# apollo510 register map
Vendor: Ambiq Micro; Series: Apollo; File version: 1.0
CPU: CM55 r1p1, little endian, MPU, FPU, double-precision FPU, DSP, I-cache, D-cache, VTOR, ITCM, DTCM, 4 interrupt priority bits, 0 interrupts, 8 SAU regions
Registers are 32-bit, read-write, reset 0x0 unless marked. A register's access mark holds for its fields unless they carry their own. Offsets are from the block's base; [hi:lo] are bit positions; {n}, {i} and the like mark numbered series; 'fields as' and 'values as' point back to an identical list.

## SDIO0 (part 1 of 2) — SDIO Control Registers
Base 0x40070000
Same registers: SDIO1 0x40071000
0x00 SDMA — SDMA system address
  [31:0] SDMASYSTEMADDRESS — This register contains the physical system memory address used for DMA transfers or the second argument for the Auto CMD23. (1) SDMA System Address This register contains the system memory address for a SDMA transfer. When the Host Controller stops a SDMA transfer, this register shall point to the system address of the next contiguous data position. It can be accessed only if no transaction is executing (i.e., after a transaction has stopped). Read operations during transfers may return an invalid value. The Host Driver shall initialize this register before starting a SDMA transaction. After SDMA has stopped, the next system address of the next contiguous data position can be read from this register. The SDMA transfer waits at the every boundary specified by the Host SDMA Buffer Boundary in the Block Size register. The Host Controller generates DMA Interrupt to request the Host Driver to update this register. The Host Driver sets the next system address of the next data position to this register. When the most upper byte of this register (003h) is written, the Host Controller restarts the SDMA transfer. When restarting SDMA by the Resume command or by setting Continue Request in the Block Gap Control register, the Host Controller shall start at the next contiguous address stored here in the SDMA System Address register. ADMA does not use this register (2) Argument 2 This register is used with the Auto CMD23 to set a 32-bit block count value to the argument of the CMD23 while executing Auto CMD23. If Auto CMD23 is used with ADMA, the full 32-bit block count value can be used. If Auto CMD23 is used without AMDA, the available block count value is limited by the Block Count register. 65535 blocks is the maximum value in this case.
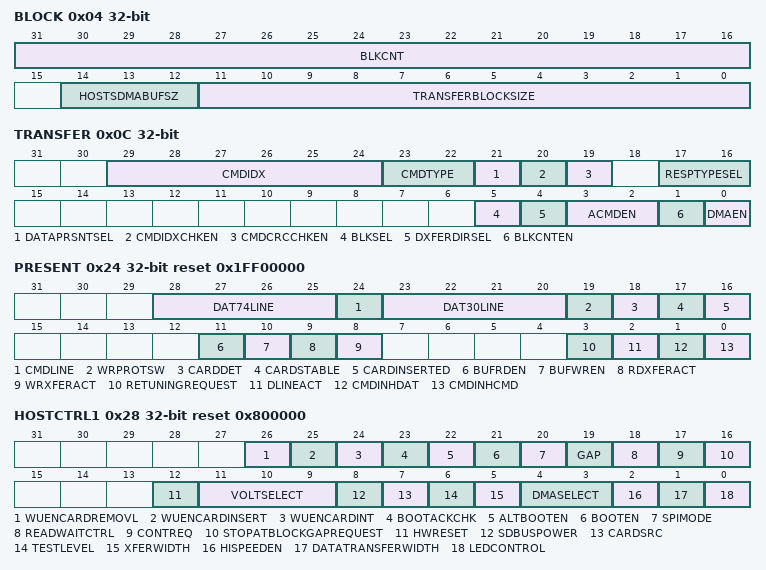
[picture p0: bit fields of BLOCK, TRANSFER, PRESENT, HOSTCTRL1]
0x04 BLOCK — Block size
  [31:16] BLKCNT — This register is enabled when Block Count Enable in the Transfer Mode register is set to 1 and is valid only for multiple block transfers. The HC decrements the block count after each block transfer and stops when the count reaches zero. It can be accessed only if no transaction is executing (i.e. after a transaction has stopped). Read operations during transfer return an invalid value and write operations shall be ignored. When saving transfer context as a result of Suspend command, the number of blocks yet to be transferred can be determined by reading this register. When restoring transfer context prior to issuing a Resume command, the HD shall restore the previously save block count.
    0=STOPCNT (Stop Count); 1=1BLOCK; 2=2BLOCKS (2 blocks (and so on from 1-65535)); 0xFFFF=65535BLOCKS
  [14:12] HOSTSDMABUFSZ — To perform long DMA transfer, System Address register shall be updated at every system boundary during DMA transfer. These bits specify the size of contiguous buffer in the system memory. The DMA transfer shall wait at the every boundary specified by these fields and the HC generates the DMA Interrupt to request the HD to update the System Address register. These bits shall support when the DMA Support in the Capabilities register is set to 1 and this function is active when the DMA Enable in the Transfer Mode register is set to 1.
    0=4KB (4KB(Detects A11 Carry out)); 1=8KB (8KB(Detects A12 Carry out)); 2=16KB (16KB(Detects A13 Carry out)); 3=32KB (32KB(Detects A14 Carry out)); 4=64KB (64KB(Detects A15 Carry out)); 5=128KB (128KB(Detects A16 Carry out)); 6=256KB (256KB(Detects A17 Carry out)); 7=512KB (512KB(Detects A18 Carry out))
  [11:0] TRANSFERBLOCKSIZE — This register specifies the block size for block data transfers for CMD17, CMD18, CMD24, CMD25, and CMD53. It can be accessed only if no transaction is executing (i.e after a transaction has stopped). Read operations during transfer return an invalid value and write operations shall be ignored.
    0=NODATAXFER (No Data Transfer); 1=1BYTE; 2=2BYTES; 3=3BYTES; 4=4BYTES (4 Bytes (and so on from 1-2048)); 0x1FF=511BYTES; 0x200=512BYTES; 0x800=2048BYTES
0x08 ARGUMENT1
  [31:0] CMDARG1 — The SD Command Argument is specified as bit39-8 of Command-Format.
0x0C TRANSFER — Transfer mode
  [29:24] CMDIDX — This bit shall be set to the command number (CMD0-63, ACMD063).
  [23:22] CMDTYPE — There are three types of special commands. Suspend, Resume and Abort. These bits shall bet set to 00b for all other commands. Suspend Command If the Suspend command succeeds, the HC shall assume the SD Bus has been released and that it is possible to issue the next command which uses the DAT line. The HC shall de-assert Read Wait for read transactions and stop checking busy for write transactions. The Interrupt cycle shall start, in 4-bit mode. If the Suspend command fails, the HC shall maintain its current state. and the HD shall restart the transfer by setting Continue Request in the Block Gap Control Register. Resume Command The HD re-starts the data transfer by restoring the registers in the range of 000-00Dh. The HC shall check for busy before starting write transfers. Abort Command If this command is set when executing a read transfer, the HC shall stop reads to the buffer. If this command is set when executing a write transfer, the HC shall stop driving the DAT line. After issuing the Abort command, the HD should issue a software reset
    0=NORMAL; 1=SUSPEND; 2=RESUME; 3=ABORT
  [21] DATAPRSNTSEL — This bit is set to 1 to indicate that data is present and shall be transferred using the DAT line. If is set to 0 for the following: 1. Commands using only CMD line (ex. CMD52) 2. Commands with no data transfer but using busy signal on DAT[0] line (R1b or R5b ex. CMD38) 3. Resume Command
    0=NODATAPRESENT; 1=DATAPRESENT
  [20] CMDIDXCHKEN — If this bit is set to 1, the HC shall check the index field in the response to see if it has the same value as the command index. If it is not, it is reported as a Command Index Error. If this bit is set to 0, the Index field is not checked.
    0=DISABLE; 1=ENABLE
  [19] CMDCRCCHKEN — If this bit is set to 1, the HC shall check the CRC field in the response. If an error is detected, it is reported as a Command CRC Error. If this bit is set to 0, the CRC field is not checked.
    0=DISABLE; 1=ENABLE
  [17:16] RESPTYPESEL — Response Type Select
    0=NORESPONSE; 1=LEN136 (Response length 136); 2=LEN48 (Response length 48); 3=LEN48CHKBUSY (Response length 48 check Busy after response)
  [5] BLKSEL — This bit enables multiple block data transfers.
    0=SINGLEBLOCK; 1=MULTIPLEBLOCK
  [4] DXFERDIRSEL — Data Transfer Direction Select. This bit defines the direction of data transfers.
    0=WRITE (Write (Host to Card)); 1=READ (Read (Card to Host))
  [3:2] ACMDEN — This field determines use of auto command functions. There are two methods to stop Multiple-block read and write operation. (1) Auto CMD12 Enable Multiple-block read and write commands for memory require CMD12 to stop the operation. When this field is set to 01b, the Host Controller issues CMD12 automatically when last block transfer is completed. Auto CMD12 error is indicated to the Auto CMD Error Status register. The Host Driver shall not set this bit if the command does not require CMD12. (2) Auto CMD23 Enable When this bit field is set to 10b, the Host Controller issues a CMD23 automatically before issuing a command specified in the Command Register The following conditions are required to use the Auto CMD23.
    0=DISABLED (Auto Command Disabled); 1=CMD12ENABLE (Auto CMD12 Enable); 2=CMD23ENABLE (Auto CMD23 Enable)
  [1] BLKCNTEN — This bit is used to enable the Block count register, which is only relevant for multiple block transfers. When this bit is 0, the Block Count register is disabled, which is useful in executing an infinite transfer.
    0=DISABLE; 1=ENABLE
  [0] DMAEN — DMA can be enabled only if DMA Support bit in the Capabilities register is set. If this bit is set to 1, a DMA operation shall begin when the HD writes to the upper byte of Command register (00Fh).
    0=DISABLE; 1=ENABLE
{0x10+4i} RESPONSE{i} (i=0..3)
  [31:0] CMDRESP{i} — R[] refers to a bit range within the response data as transmitted on the SD Bus, REP[] refers to a bit range within the Response register.
0x20 BUFFER — Buffer data port
  [31:0] BUFFERDATA — The Host Controller Buffer can be accessed through this 32-bit Data Port Register.
0x24 PRESENT reset 0x1FF00000 — Present state
  [28:25] DAT74LINE — This status is used to check DAT line level to recover from errors, and for debugging.
    8=DAT7; 4=DAT6; 2=DAT5; 1=DAT4
  [24] CMDLINE — This status is used to check CMD line level to recover from errors, and for debugging.
  [23:20] DAT30LINE — This status is used to check DAT line level to recover from errors, and for debugging. This is especially useful in detecting the busy signal level from DAT[0].
    8=DAT3; 4=DAT2; 2=DAT1; 1=DAT0
  [19] WRPROTSW — The Write Protect Switch is supported for memory and combo cards. This bit reflects the SDWP# pin.
    0=WRITEPROTECTED (Write protected (SDWP# = 0)); 1=WRITEENABLED (Write enabled (SDWP# = 1))
  [18] CARDDET — This bit reflects the inverse value of the SDCD# pin.
    0=NOCARDPRESENT (No Card present (SDCD# = 1)); 1=CARDPRESENT (Card present (SDCD# = 0))
  [17] CARDSTABLE — This bit is used for testing. If it is 0, the Card Detect Pin Level is not stable. If this bit is set to 1, it means the Card Detect Pin Level is stable. The Software Reset For All in the Software Reset Register shall not affect this bit.
    0=RESET_DEBOUNCING_NOCARD (Reset or Debouncing or No Card); 1=CARDINSERTED
  [16] CARDINSERTED — This bit indicates whether a card has been inserted. Changing from 0 to 1 generates a Card Insertion interrupt in the Normal Interrupt Status register and changing from 1 to 0 generates a Card Removal Interrupt in the Normal Interrupt Status register. The Software Reset For All in the Software Reset register shall not affect this bit. If a Card is removed while its power is on and its clock is oscillating, the HC shall clear SD Bus Power in the Power Control register and SD Clock Enable in the Clock control register. In addition the HD should clear the HC by the Software Reset For All in Software register. The card detect is active regardless of the SD Bus Power.
    values as CARDSTABLE
  [11] BUFRDEN — This status is used for non-DMA read transfers. This read only flag indicates that valid data exists in the host side buffer status. If this bit is 1, readable data exists in the buffer. A change of this bit from 1 to 0 occurs when all the block data is read from the buffer. A change of this bit from 0 to 1 occurs when all the block data is ready in the buffer and generates the Buffer Read Ready Interrupt.
    0=DISABLE (Read Disable); 1=ENABLE (Read Enable.)
  [10] BUFWREN — This status is used for non-DMA write transfers. This read only flag indicates if space is available for write data. If this bit is 1, data can be written to the buffer. A change of this bit from 1 to 0 occurs when all the block data is written to the buffer. A change of this bit from 0 to 1 occurs when top of block data can be written to the buffer and generates the Buffer Write Ready Interrupt.
    0=DISABLE (Write Disable); 1=ENABLE (Write Enable.)
  [9] RDXFERACT — This status is used for detecting completion of a read transfer. This bit is set to 1 for either of the following conditions: After the end bit of the read command When writing a 1 to continue Request in the Block Gap Control register to restart a read transfer This bit is cleared to 0 for either of the following conditions: When the last data block as specified by block length is transferred to the system. When all valid data blocks have been transferred to the system and no current block transfers are being sent as a result of the Stop At Block Gap Request set to 1. A transfer complete interrupt is generated when this bit changes to 0.
    1=TRANSFERRING (Transferring data); 0=NOVALIDATA (No valid data)
  [8] WRXFERACT — This status indicates a write transfer is active. If this bit is 0, it means no valid write data exists in the HC. This bit is set in either of the following cases: After the end bit of the write command. When writing a 1 to Continue Request in the Block Gap Control register to restart a write transfer. This bit is cleared in either of the following cases: After getting the CRC status of the last data block as specified by the transfer count (Single or Multiple) After getting a CRC status of any block where data transmission is about to be stopped by a Stop At Block Gap Request. During a write transaction, a Block Gap Event interrupt is generated when this bit is changed to 0, as a result of the Stop At Block Gap Request being set. This status is useful for the HD in determining when to issue commands during write busy.
    1=TRANSFERRING (transferring data); 0=NOVALIDDATA
  [3] RETUNINGREQUEST — Re-Tuning Request Host Controller may request Host Driver to execute re-tuning sequence by setting this bit when the data window is shifted by temperature drift and a tuned sampling point does not have a good margin to receive correct data. This bit is cleared when a command is issued with setting Execute Tuning in the Host Control 2 register. Changing of this bit from 0 to 1 generates Re-Tuning Event. Refer to Normal Interrupt registers for more detail. This bit isn't set to 1 if Sampling Clock Select in the Host Control 2 register is set to 0 (using fixed sampling clock).
    1=RETUNENEEDED (Sampling clock needs re-tuning); 0=WELLTUNED (Fixed or well tuned sampling clock)
  [2] DLINEACT — This bit indicates whether one of the DAT line on SD bus is in use.
    1=ACTIVE (DAT line active); 0=INACTIVE (DAT line inactive)
  [1] CMDINHDAT — This status bit is generated if either the DAT Line Active or the Read transfer Active is set to 1. If this bit is 0, it indicates the HC can issue the next SD command. Commands with busy signal belong to Command Inhibit (DAT) (ex. R1b, R5b type). Changing from 1 to 0 generates a Transfer Complete interrupt in the Normal interrupt status register. Note: The SD Host Driver can save registers in the range of 000-00Dh for a suspend transaction after this bit has changed from 1 to 0.
    1=DONTISSUE (cannot issue command which uses the DAT line); 0=ISSUE (Can issue command which uses the DAT line)
  [0] CMDINHCMD — If this bit is 0, it indicates the CMD line is not in use and the HC can issue a SD command using the CMD line. This bit is set immediately after the Command register (00Fh) is written. This bit is cleared when the command response is received. Even if the Command Inhibit (DAT) is set to 1, Commands using only the CMD line can be issued if this bit is 0. Changing from 1 to 0 generates a Command complete interrupt in the Normal Interrupt Status register. If the HC cannot issue the command because of a command conflict error or because of Command Not Issued By Auto CMD12 Error, this bit shall remain 1 and the Command Complete is not set. Status issuing Auto CMD12 is not read from this bit. Auto CMD12 and Auto CMD23 consist of two responses. In this case, this bit is not cleared by the response of CMD12 or CMD23 but cleared by the response of a read/write command. Status issuing Auto CMD12 is not read from this bit. So if a command is issued during Auto CMD12 operation, Host Controller shall manage to issue two commands: CMD12 and a command set by Command register. Note: DAT line active indicates whether one of the DAT line is on SD bus is in use. (a) In the case of read transactions This status indicates whether a read transfer is executing on the SD Bus. Changing this value from 1 to 0 generates a Block Gap Event interrupt in the Normal Interrupt Status register, as the result of the Stop At Block Gap Request being set. This bit shall be set in either of the following cases: (1) After the end bit of the read command. (2) When writing a 1 to Continue Request in the Block Gap Control register to restart a read transfer. This bit shall be cleared in either of the following cases: (1) When the end bit of the last data block is sent from the SD Bus to the Host Controller. In case of ADMA2, the last block is designated by the last transfer of Descriptor Table. (2) When a read transfer is stopped at the block gap initiated by a Stop At Block Gap Request. The Host Controller shall stop read operation at the start of the interrupt cycle of the next block gap by driving Read Wait or stopping SD clock. If the Read Wait signal is already driven (due to data buffer cannot receive data), the Host Controller can continue to stop read operation by driving the Read Wait signal. It is necessary to support Read Wait in order to use suspend / resume function. (b) In the case of write transactions This status indicates that a write transfer is executing on the SD Bus. Changing this value from 1 to 0 generate a Transfer Complete interrupt in the Normal Interrupt Status register. This bit shall be set in either of the following cases: (1) After the end bit of the write command. (2) When writing to 1 to Continue Request in the Block Gap Control register to continue a write transfer. This bit shall be cleared in either of the following cases: (1) When the SD card releases write busy of the last data block. If SD card does not drive busy signal for 8 SD Clocks, the Host Controller shall consider the card drive Not Busy. In case of ADMA2, the last block is designated by the last transfer of Descriptor Table. (2) When the SD card releases write busy prior to waiting for write transfer as a result of a Stop At Block Gap Request. (c) Command with busy This status indicates whether a command indicates busy (ex. erase command for memory) is executing on the SD Bus. This bit is set after the end bit of the command with busy and cleared when busy is de-asserted. Changing this bit from 1 to 0 generate a Transfer Complete interrupt in the Normal Interrupt Status register. Note: The HD can issue cmd0, cmd12, cmd13 (for memory) and cmd52 (for SDIO) when the DAT lines are busy during data transfer. These commands can be issued when Command Inhibit (CMD) is set to zero. Other commands shall be issued when Command Inhibit (DAT) is set to zero.
    1=DONTISSUE (CMD line is in use); 0=ISSUE (Indicates that the CMD line is not in use and the HC can issue a SD command using the CMD line.)
0x28 HOSTCTRL1 reset 0x800000 — Host control 1
  [26] WUENCARDREMOVL — This bit enables wakeup event via Card Removal assertion in the Normal Interrupt Status register. FN_WUS (Wake up Support) in CIS does not affect this bit.
    1=ENABLE; 0=DISABLE
  [25] WUENCARDINSERT — This bit enables wakeup event via Card Insertion assertion in the Normal Interrupt Status register. FN_WUS (Wake up Support) in CIS does not affect this bit.
    1=ENABLE; 0=DISABLE
  [24] WUENCARDINT — This bit enables wakeup event via Card Interrupt assertion in the Normal Interrupt Status register. This bit can be set to 1 if FN_WUS (Wake Up Support) in CIS is set to 1.
    1=ENABLE; 0=DISABLE
  [23] BOOTACKCHK — To check for the boot acknowledge in boot operation.
    1=WAIT (wait for boot ack from eMMC card); 0=NOWAIT (Will not wait for boot ack from eMMC card)
  [22] ALTBOOTEN — To start boot code access in alternative mode.
    1=START (To start alternate boot mode access); 0=STOP (To stop alternate boot mode access)
  [21] BOOTEN — To start boot code access
    1=START (To start boot code access); 0=STOP (To stop boot code access)
  [20] SPIMODE — SPI mode enable bit.
    1=SPI (SPI mode); 0=SD (SD mode)
  [19] GAP — This bit is valid only in 4-bit mode of the SDIO card and selects a sample point in the interrupt cycle. Setting to 1 enables interrupt detection at the block gap for a multiple block transfer. If the SD card cannot signal an interrupt during a multiple block transfer, this bit should be set to 0. When the HD detects an SD card insertion, it shall set this bit according to the CCCR of the SDIO card.
  [18] READWAITCTRL — The read wait function is optional for SDIO cards. If the card supports read wait, set this bit to enable use of the read wait protocol to stop read data using DAT[2] line. Otherwise the HC has to stop the SD clock to hold read data, which restricts commands generation. When the HD detects an SD card insertion, it shall set this bit according to the CCCR of the SDIO card. If the card does not support read wait, this bit shall never be set to 1 otherwise DAT line conflict may occur. If this bit is set to 0, Suspend / Resume cannot be supported
    1=ENABLE (Enable Read Wait Control); 0=DISABLE (Disable Read Wait Control)
  [17] CONTREQ — This bit is used to restart a transaction which was stopped using the Stop At Block Gap Request. To cancel stop at the block gap, set Stop At block Gap Request to 0 and set this bit to restart the transfer. The HC automatically clears this bit in either of the following cases: 1) In the case of a read transaction, the DAT Line Active changes from 0 to 1 as a read transaction restarts. 2) In the case of a write transaction, the Write transfer active changes from 0 to 1 as the write transaction restarts. Therefore it is not necessary for Host driver to set this bit to 0. If Stop At Block Gap Request is set to 1, any write to this bit is ignored.
    1=RESTART; 0=IGNORED
  [16] STOPATBLOCKGAPREQUEST — This bit is used to stop executing a transaction at the next block gap for non- DMA,SDMA and ADMA transfers. Until the transfer complete is set to 1, indicating a transfer completion the HD shall leave this bit set to 1. Clearing both the Stop At Block Gap Request and Continue Request shall not cause the transaction to restart. Read Wait is used to stop the read transaction at the block gap. The HC shall honour Stop At Block Gap Request for write transfers, but for read transfers it requires that the SD card support Read Wait. Therefore the HD shall not set this bit during read transfers unless the SD card supports Read Wait and has set Read Wait Control to 1. In case of write transfers in which the HD writes data to the Buffer Data Port register, the HD shall set this bit after all block data is written. If this bit is set to 1, the HD shall not write data to Buffer data port register. This bit affects Read Transfer Active, Write Transfer Active, DAT line active and Command Inhibit (DAT) in the Present State register.
    1=STOP; 0=TRANSFER
  [12] HWRESET — Hardware reset signal is generated for eMMC card when this bit is set
    1=ASSERT (Drives the hardware reset pin as ZERO (Active LOW to eMMC card)); 0=DEASSERT (Deassert the hardware reset pin)
  [11:9] VOLTSELECT — By setting these bits, the HD selects the voltage level for the SD card. Before setting this register, the HD shall check the voltage support bits in the capabilities register. If an unsupported voltage is selected, the Host System shall not supply SD bus voltage. All voltage select values not enumerated here are reserved.
    7=3_3V (3.3 V(Typ.)); 6=3_0V (3.0 V(Typ.)); 5=1_8V (1.8 V(Typ.))
  [8] SDBUSPOWER — Before setting this bit, the SD host driver shall set SD Bus Voltage Select. If the HC detects the No Card State, this bit shall be cleared.
    1=POWERON; 0=POWEROFF
  [7] CARDSRC — This bit selects source for card detection.
    1=TEST (The card detect test level is selected); 0=SDCD (SDCD is selected (for normal use))
  [6] TESTLEVEL — This bit is enabled while the Card Detect Signal Selection is set to 1 and it indicates card inserted or not. Generates (card ins or card removal) interrupt when the normal int sts enable bit is set.
    1=CARDINSERTED; 0=NOCARD
  [5] XFERWIDTH — This bit controls 8-bit bus width mode for embedded device. Support of this function is indicated in 8-bit Support for Embedded Device in the Capabilities register. If a device supports 8-bit bus mode, this bit may be set to 1. If this bit is 0, bus width is controlled by Data Transfer Width in the Host Control 1 register.This bit is not effective when multiple devices are installed on a bus slot (Slot Type is set to 10b in the Capabilities register). In this case, each device bus width is controlled by Bus Width Preset field in the Shared Bus register.
    1=8BIT (8-bit Bus Width); 0=XFER (Bus Width is selected by Data Transfer Width)
  [4:3] DMASELECT — One of supported DMA modes can be selected. The host driver shall check support of DMA modes by referring the Capabilities register.
    0=SDMA (SDMA is selected); 1=ADMA132 (32-bit Address ADMA1 is selected); 2=ADMA232 (32-bit Address ADMA2 is selected); 3=ADMA264 (64-bit Address ADMA2 is selected)
  [2] HISPEEDEN — This bit is optional. Before setting this bit, the HD shall check the High Speed Support in the capabilities register. If this bit is set to 0 (default), the HC outputs CMD line and DAT lines at the falling edge of the SD clock (up to 25 MHz/ 20MHz for MMC). If this bit is set to 1, the HC outputs CMD line and DAT lines at the rising edge of the SD clock (up to 50 MHz for SD/52MHz for MMC)/ 208Mhz (for SD3.0) If Preset Value Enable in the Host Control 2 register is set to 1, Host Driver needs to reset SD Clock Enable before changing this field to avoid generating clock glitches. After setting this field, the Host Driver sets SD Clock Enable again
    1=HIGH (High Speed Mode); 0=NORMAL (Normal Speed Mode)
  [1] DATATRANSFERWIDTH — (SD1 or SD4) This bit selects the data width of the HC. The HD shall select it to match the data width of the SD card.
    1=SD4 (4 bit mode); 0=SD1 (1 bit mode)
  [0] LEDCONTROL — This bit is used to caution the user not to remove the card while the SD card is being accessed. If the software is going to issue multiple SD commands, this bit can be set during all transactions. It is not necessary to change for each transaction.
    1=ON (LED on); 0=OFF (LED off)
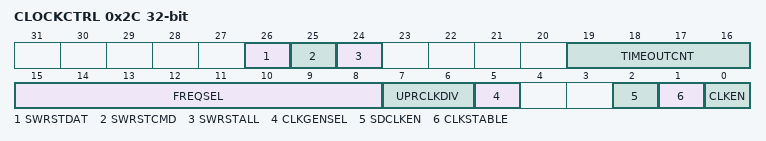
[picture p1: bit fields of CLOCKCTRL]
0x2C CLOCKCTRL — Clock control
  [26] SWRSTDAT — Only part of data circuit is reset. The following registers and bits are cleared by this bit: Buffer Data Port Register Buffer is cleared and Initialized. Present State register Buffer read Enable Buffer write Enable Read Transfer Active Write Transfer Active DAT Line Active Command Inhibit (DAT) Block Gap Control register Continue Request Stop At Block Gap Request Normal Interrupt Status register Buffer Read Ready Buffer Write Ready Block Gap Event Transfer Complete
    1=RESET; 0=WORK
  [25] SWRSTCMD — Only part of command circuit is reset. The following registers and bits are cleared by this bit: Present State register Command Inhibit (CMD) Normal Interrupt Status register Command Complete
    1=RESET; 0=WORK
  [24] SWRSTALL — This reset affects the entire HC except for the card detection circuit. Register bits of type ROC, RW, RW1C, RWAC are cleared to 0. During its initialization, the HD shall set this bit to 1 to reset the HC. The HC shall reset this bit to 0 when capabilities registers are valid and the HD can read them. Additional use of Software Reset For All may not affect the value of the Capabilities registers. If this bit is set to 1, the SD card shall reset itself and must be re initialized by the HD. A reset pulse is generated when writing 1 to each bit of this register. After completing the reset, the HC shall clear each bit. Because it takes some time to complete software reset, the SD Host Driver shall confirm that these bits are 0.
    1=RESET; 0=WORK
  [19:16] TIMEOUTCNT — This value determines the interval by which DAT line time-outs are detected. Refer to the Data Time-out Error in the Error Interrupt Status register for information on factors that dictate time-out generation. Time-out clock frequency will be generated by dividing the sdclockTMCLK by this value. When setting this register, prevent inadvertent time-out events by clearing the Data Time-out Error Status Enable (in the Error Interrupt Status Enable register) At the initialization of the HC, the HD shall set the Data Time-out Counter Value according to the Capabilities register. The general formula is TIMEOUT = 2 ^ (TIMEOUTCNT + 13).
    {v}=TMCLK * 2^{v+13} (v=0..14)
  [15:8] FREQSEL — This register is used to select the frequency of the SDCLK pin. The frequency is not programmed directly; rather this register holds the divisor of the Base Clock Frequency For SD clock in the capabilities register. Only the following settings are allowed. (1) 8-bit Divided Clock Mode Setting 00h specifies the highest frequency of the SD Clock. When setting multiple bits, the most significant bit is used as the divisor. But multiple bits should not be set. The two default divider values can be calculated by the frequency that is defined by the Base Clock Frequency For SD Clock in the Capabilities register. 1) 25 MHz divider value 2) 400 KHz divider value The frequency of the SDCLK is set by the following formula: Clock Frequency = (Baseclock) / divisor. Thus choose the smallest possible divisor which results in a clock frequency that is less than or equal to the target frequency. Maximum Frequency for SD = 50Mhz (base clock) Maximum Frequency for MMC = 52Mhz (base clock) Minimum Frequency = 195.3125Khz (50Mhz / 256), same calculation for MMC also (2) 10-bit Divided Clock Mode Host Controller Version 3.00 supports this mandatory mode instead of the 8-bit Divided Clock Mode. The length of divider is extended to10 bits and all divider values shall be supported. 3FFh --1/2046 Divided Clock N -------1/2N Divided Clock (Duty 50%) 002h -- 1/4 Divided Clock 001h ---1/2 Divided Clock 000h --- Base Clock (10MHz-254MHz)
    128=DIV256 (base clock divided by 256); 64=DIV128 (base clock divided by 128); 32=DIV64 (base clock divided by 64); 16=DIV32 (base clock divided by 32); 8=DIV16 (base clock divided by 16); 4=DIV8 (base clock divided by 8); 2=DIV4 (base clock divided by 4); 1=DIV2 (base clock divided by 2); 0=BASECLK (Base clock (10MHz - 63MHz))
  [7:6] UPRCLKDIV — Bit 07-06 is assigned to bit 09-08 of clock divider in SDCLK Frequency Select
  [5] CLKGENSEL — This bit is used to select the clock generator mode in SDCLK Frequency Select. If the Programmable Clock Mode is supported (non-zero value is set to Clock Multiplier in the Capabilities register), this bit attribute is RW, and if not supported, this bit attribute is RO and zero is read. This bit depends on the setting of Preset Value Enable in the Host Control 2 register. If the Preset Value Enable = 0, this bit is set by Host Driver. If the Preset Value Enable = 1, this bit is automatically set to a value specified in one of Preset Value registers.
    1=PROGCLK (Programmable Clock Mode); 0=DIVCLK (Divided Clock Mode)
  [2] SDCLKEN — The HC shall stop SDCLK when writing this bit to 0. SDCLK frequency Select can be changed when this bit is 0. Then, the HC shall maintain the same clock frequency until SDCLK is stopped (Stop at SDCLK = 0). If the HC detects the No Card state, this bit shall be cleared.
    1=ENABLE; 0=DISABLE
  [1] CLKSTABLE — This bit is set to 1 when SD clock is stable after writing to Internal Clock Enable in this register to 1. The SD Host Driver shall wait to set SD Clock Enable until this bit is set to 1. Note: This is useful when using PLL for a clock oscillator that requires setup time.
    1=READY; 0=NOTREADY
  [0] CLKEN — This bit is set to 0 when the HD is not using the HC or the HC awaits a wakeup event. The HC should stop its internal clock to go very low power state. Still, registers shall be able to be read and written. Clock starts to oscillate when this bit is set to 1. When clock oscillation is stable, the HC shall set Internal Clock Stable in this register to 1. This bit shall not affect card detection.
    1=OSC (Oscillate); 0=STOP
